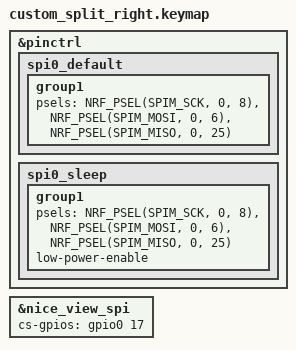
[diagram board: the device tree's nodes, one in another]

&pinctrl {
    spi0_default: spi0_default {
        group1 {
            psels = <NRF_PSEL(SPIM_SCK, 0, 8)>,
                <NRF_PSEL(SPIM_MOSI, 0, 6)>,
                <NRF_PSEL(SPIM_MISO, 0, 25)>;
        };
    };
    spi0_sleep: spi0_sleep {
        group1 {
            psels = <NRF_PSEL(SPIM_SCK, 0, 8)>,
                <NRF_PSEL(SPIM_MOSI, 0, 6)>,
                <NRF_PSEL(SPIM_MISO, 0, 25)>;
            low-power-enable;
        };
    };
};

&nice_view_spi {
    cs-gpios = <&gpio0 17 GPIO_ACTIVE_HIGH>;
};
